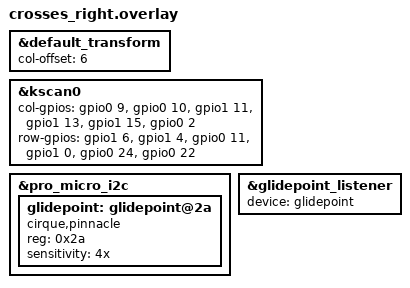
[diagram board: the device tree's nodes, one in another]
#include "crosses.dtsi"
#include <zephyr/dt-bindings/input/input-event-codes.h>

/* Default keymap transform */
&default_transform {
    col-offset = <6>;
};

/* Key matrix */
&kscan0 {
    col-gpios = 
        <&gpio0 9 GPIO_ACTIVE_HIGH>,
        <&gpio0 10 GPIO_ACTIVE_HIGH>,
        <&gpio1 11 GPIO_ACTIVE_HIGH>,
        <&gpio1 13 GPIO_ACTIVE_HIGH>,
        <&gpio1 15 GPIO_ACTIVE_HIGH>,
        <&gpio0 2 GPIO_ACTIVE_HIGH>;

    row-gpios = 
        <&gpio1 6 (GPIO_ACTIVE_HIGH | GPIO_PULL_DOWN)>,
        <&gpio1 4 (GPIO_ACTIVE_HIGH | GPIO_PULL_DOWN)>,
        <&gpio0 11 (GPIO_ACTIVE_HIGH | GPIO_PULL_DOWN)>,
        <&gpio1 0 (GPIO_ACTIVE_HIGH | GPIO_PULL_DOWN)>,
        <&gpio0 24 (GPIO_ACTIVE_HIGH | GPIO_PULL_DOWN)>,
        <&gpio0 22 (GPIO_ACTIVE_HIGH | GPIO_PULL_DOWN)>;
};
/*
&pinctrl {
    i2c0_default {
        group1 {
            psels = <NRF_PSEL(TWIM_SDA, 1, 00)>,
                <NRF_PSEL(TWIM_SCL, 0, 11)>;
            bias-pull-up;
        };
    };
    i2c0_sleep: i2c0_sleep {
        group1 {
            psels = <NRF_PSEL(TWIM_SDA, 1, 00)>,
                <NRF_PSEL(TWIM_SCL, 0, 11)>;
            low-power-enable;
        };
    };
};
*/
&pro_micro_i2c {
    status = "okay";
    glidepoint: glidepoint@2a {
        compatible = "cirque,pinnacle";
        status = "okay";
        reg = <0x2a>;
        // Note that this is only applicable in v1.1 or above
        // dr-gpios = <&gpio0 6 (GPIO_ACTIVE_HIGH)>;
        sensitivity = "4x";
    };
};

&glidepoint_listener {
    status = "okay";
    device = <&glidepoint>;
};
